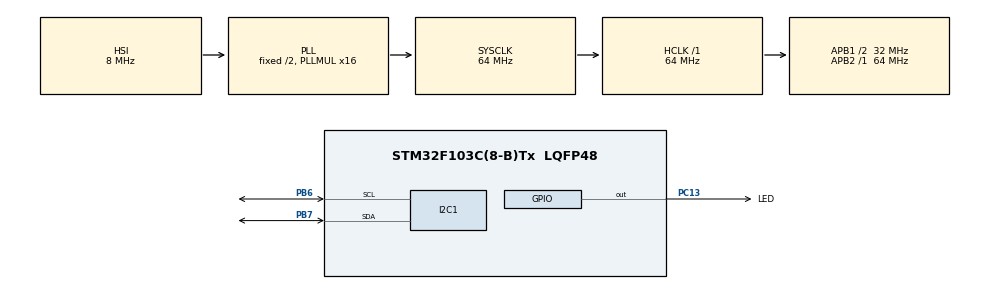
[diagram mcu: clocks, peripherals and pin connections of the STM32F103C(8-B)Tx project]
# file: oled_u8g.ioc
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Mcu.Family=STM32F1
Mcu.Name=STM32F103C(8-B)Tx
Mcu.Package=LQFP48
NVIC.PriorityGroup=NVIC_PRIORITYGROUP_4
PA13.Mode=Serial_Wire
PA13.Signal=SYS_JTMS-SWDIO
PA14.Mode=Serial_Wire
PA14.Signal=SYS_JTCK-SWCLK
PB6.Mode=I2C
PB6.Signal=I2C1_SCL
PB7.Mode=I2C
PB7.Signal=I2C1_SDA
PC13-TAMPER-RTC.GPIO_Label=LED
PC13-TAMPER-RTC.Signal=GPIO_Output
ProjectManager.HeapSize=0x400
ProjectManager.StackSize=0x800
ProjectManager.TargetToolchain=MDK-ARM V5
RCC.AHBFreq_Value=64000000
RCC.APB1CLKDivider=RCC_HCLK_DIV2
RCC.APB1Freq_Value=32000000
RCC.APB1TimFreq_Value=64000000
RCC.APB2Freq_Value=64000000
RCC.APB2TimFreq_Value=64000000
RCC.HCLKFreq_Value=64000000
RCC.PLLMUL=RCC_PLL_MUL16
RCC.SYSCLKFreq_VALUE=64000000
RCC.SYSCLKSource=RCC_SYSCLKSOURCE_PLLCLK
RCC.USBFreq_Value=64000000
board=oled_u8g

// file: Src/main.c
/**
  ******************************************************************************
  * @file           : main.c
  * @brief          : Main program body
  ******************************************************************************
  ** This notice applies to any and all portions of this file
  * that are not between comment pairs USER CODE BEGIN and
  * USER CODE END. Other portions of this file, whether
  * inserted by the user or by software development tools
  * are owned by their respective copyright owners.
  *
  * COPYRIGHT(c) 2019 STMicroelectronics
  *
  * Redistribution and use in source and binary forms, with or without modification,
  * are permitted provided that the following conditions are met:
  *   1. Redistributions of source code must retain the above copyright notice,
  *      this list of conditions and the following disclaimer.
  *   2. Redistributions in binary form must reproduce the above copyright notice,
  *      this list of conditions and the following disclaimer in the documentation
  *      and/or other materials provided with the distribution.
  *   3. Neither the name of STMicroelectronics nor the names of its contributors
  *      may be used to endorse or promote products derived from this software
  *      without specific prior written permission.
  *
  * THIS SOFTWARE IS PROVIDED BY THE COPYRIGHT HOLDERS AND CONTRIBUTORS "AS IS"
  * AND ANY EXPRESS OR IMPLIED WARRANTIES, INCLUDING, BUT NOT LIMITED TO, THE
  * IMPLIED WARRANTIES OF MERCHANTABILITY AND FITNESS FOR A PARTICULAR PURPOSE ARE
  * DISCLAIMED. IN NO EVENT SHALL THE COPYRIGHT HOLDER OR CONTRIBUTORS BE LIABLE
  * FOR ANY DIRECT, INDIRECT, INCIDENTAL, SPECIAL, EXEMPLARY, OR CONSEQUENTIAL
  * DAMAGES (INCLUDING, BUT NOT LIMITED TO, PROCUREMENT OF SUBSTITUTE GOODS OR
  * SERVICES; LOSS OF USE, DATA, OR PROFITS; OR BUSINESS INTERRUPTION) HOWEVER
  * CAUSED AND ON ANY THEORY OF LIABILITY, WHETHER IN CONTRACT, STRICT LIABILITY,
  * OR TORT (INCLUDING NEGLIGENCE OR OTHERWISE) ARISING IN ANY WAY OUT OF THE USE
  * OF THIS SOFTWARE, EVEN IF ADVISED OF THE POSSIBILITY OF SUCH DAMAGE.
  *
  ******************************************************************************
  */
#include "main.h"
#include "stm32f1xx_hal.h"

/* USER CODE BEGIN Includes */
#include "u8g_arm.h"
/* USER CODE END Includes */

I2C_HandleTypeDef hi2c1;

/* USER CODE BEGIN PV */
/* Private variables ---------------------------------------------------------*/
static u8g_t u8g;
/* USER CODE END PV */

void SystemClock_Config(void);
static void MX_GPIO_Init(void);
static void MX_I2C1_Init(void);

/* USER CODE BEGIN PFP */
/* Private function prototypes -----------------------------------------------*/

/* USER CODE END PFP */

/* USER CODE BEGIN 0 */
/*
Function which responds for drawing
*/
void draw(void)
{
     u8g_SetFont(&u8g,u8g_font_profont10);//set current font
     u8g_DrawStr(&u8g, 2, 12, "Hello!");//write string - you set coordinates and string
     u8g_DrawBox(&u8g, 30, 30, 35, 35);//draw some box
}
/* USER CODE END 0 */

int main(void)
{

  /* MCU Configuration----------------------------------------------------------*/

  /* Reset of all peripherals, Initializes the Flash interface and the Systick. */
  HAL_Init();

  /* Configure the system clock */
  SystemClock_Config();

  /* Initialize all configured peripherals */
  MX_GPIO_Init();
  MX_I2C1_Init();
  /* USER CODE BEGIN 2 */
  /* init u8glib driver */
  u8g_InitComFn(&u8g, &u8g_dev_ssd1306_128x64_i2c, u8g_com_hw_i2c_fn);
  /* USER CODE END 2 */

  /* Infinite loop */
  /* USER CODE BEGIN WHILE */
  while (1)
  {
  //this loop correspond of drawing
  u8g_FirstPage(&u8g);

    do
    {
      draw();
    } while ( u8g_NextPage(&u8g) );

  u8g_Delay(10);

  /* USER CODE END WHILE */

  }

}

void SystemClock_Config(void)
{

  RCC_OscInitTypeDef RCC_OscInitStruct;
  RCC_ClkInitTypeDef RCC_ClkInitStruct;

    /**Initializes the CPU, AHB and APB busses clocks
    */
  RCC_OscInitStruct.OscillatorType = RCC_OSCILLATORTYPE_HSI;
  RCC_OscInitStruct.HSIState = RCC_HSI_ON;
  RCC_OscInitStruct.HSICalibrationValue = 16;
  RCC_OscInitStruct.PLL.PLLState = RCC_PLL_ON;
  RCC_OscInitStruct.PLL.PLLSource = RCC_PLLSOURCE_HSI_DIV2;
  RCC_OscInitStruct.PLL.PLLMUL = RCC_PLL_MUL16;
  if (HAL_RCC_OscConfig(&RCC_OscInitStruct) != HAL_OK)
  {
    _Error_Handler(__FILE__, __LINE__);
  }

    /**Initializes the CPU, AHB and APB busses clocks
    */
  RCC_ClkInitStruct.ClockType = RCC_CLOCKTYPE_HCLK|RCC_CLOCKTYPE_SYSCLK
                              |RCC_CLOCKTYPE_PCLK1|RCC_CLOCKTYPE_PCLK2;
  RCC_ClkInitStruct.SYSCLKSource = RCC_SYSCLKSOURCE_PLLCLK;
  RCC_ClkInitStruct.AHBCLKDivider = RCC_SYSCLK_DIV1;
  RCC_ClkInitStruct.APB1CLKDivider = RCC_HCLK_DIV2;
  RCC_ClkInitStruct.APB2CLKDivider = RCC_HCLK_DIV1;

  if (HAL_RCC_ClockConfig(&RCC_ClkInitStruct, FLASH_LATENCY_2) != HAL_OK)
  {
    _Error_Handler(__FILE__, __LINE__);
  }

    /**Configure the Systick interrupt time
    */
  HAL_SYSTICK_Config(HAL_RCC_GetHCLKFreq()/1000);

    /**Configure the Systick
    */
  HAL_SYSTICK_CLKSourceConfig(SYSTICK_CLKSOURCE_HCLK);

  /* SysTick_IRQn interrupt configuration */
  HAL_NVIC_SetPriority(SysTick_IRQn, 0, 0);
}

/* I2C1 init function */
static void MX_I2C1_Init(void)
{

  hi2c1.Instance = I2C1;
  hi2c1.Init.ClockSpeed = 100000;
  hi2c1.Init.DutyCycle = I2C_DUTYCYCLE_2;
  hi2c1.Init.OwnAddress1 = 0;
  hi2c1.Init.AddressingMode = I2C_ADDRESSINGMODE_7BIT;
  hi2c1.Init.DualAddressMode = I2C_DUALADDRESS_DISABLE;
  hi2c1.Init.OwnAddress2 = 0;
  hi2c1.Init.GeneralCallMode = I2C_GENERALCALL_DISABLE;
  hi2c1.Init.NoStretchMode = I2C_NOSTRETCH_DISABLE;
  if (HAL_I2C_Init(&hi2c1) != HAL_OK)
  {
    _Error_Handler(__FILE__, __LINE__);
  }

}

/** Configure pins as
        * Analog
        * Input
        * Output
        * EVENT_OUT
        * EXTI
*/
static void MX_GPIO_Init(void)
{

  GPIO_InitTypeDef GPIO_InitStruct;

  /* GPIO Ports Clock Enable */
  __HAL_RCC_GPIOC_CLK_ENABLE();
  __HAL_RCC_GPIOA_CLK_ENABLE();
  __HAL_RCC_GPIOB_CLK_ENABLE();

  /*Configure GPIO pin Output Level */
  HAL_GPIO_WritePin(LED_GPIO_Port, LED_Pin, GPIO_PIN_RESET);

  /*Configure GPIO pin : LED_Pin */
  GPIO_InitStruct.Pin = LED_Pin;
  GPIO_InitStruct.Mode = GPIO_MODE_OUTPUT_PP;
  GPIO_InitStruct.Speed = GPIO_SPEED_FREQ_LOW;
  HAL_GPIO_Init(LED_GPIO_Port, &GPIO_InitStruct);

}

void _Error_Handler(char *file, int line)
{
  while(1)
  {
  }
}

/************************ (C) COPYRIGHT STMicroelectronics *****END OF FILE****/
